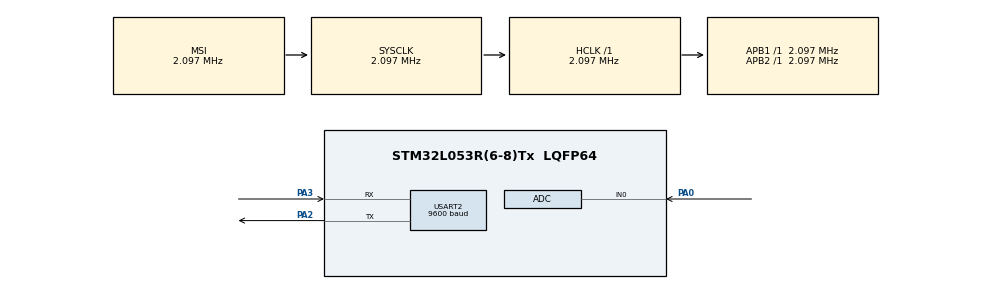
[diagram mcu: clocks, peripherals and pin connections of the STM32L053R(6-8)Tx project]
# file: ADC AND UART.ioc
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ADC.DiscontinuousConvMode=ENABLE
Mcu.Family=STM32L0
Mcu.Name=STM32L053R(6-8)Tx
Mcu.Package=LQFP64
NVIC.RCC_CRS_IRQn=true\:0\:0\:false\:false\:true\:true\:false\:true
PA0.Mode=IN0
PA0.Signal=ADC_IN0
PA2.Mode=Multiprocessor_communication
PA2.Signal=USART2_TX
PA3.Mode=Multiprocessor_communication
PA3.Signal=USART2_RX
PH0-OSC_IN.Mode=HSE-External-Oscillator
PH0-OSC_IN.Signal=RCC_OSC_IN
PH1-OSC_OUT.Mode=HSE-External-Oscillator
PH1-OSC_OUT.Signal=RCC_OSC_OUT
ProjectManager.HeapSize=0x200
ProjectManager.StackSize=0x400
ProjectManager.TargetToolchain=STM32CubeIDE
RCC.AHBFreq_Value=2097000
RCC.APB1Freq_Value=2097000
RCC.APB1TimFreq_Value=2097000
RCC.APB2Freq_Value=2097000
RCC.APB2TimFreq_Value=2097000
RCC.HSE_VALUE=8000000
RCC.HSI16_VALUE=16000000
RCC.HSI48_VALUE=48000000
RCC.HSI_VALUE=16000000
RCC.LSE_VALUE=32768
RCC.MSI_VALUE=2097000
RCC.SYSCLKFreq_VALUE=2097000
RCC.VCOOutputFreq_Value=48000000
USART2.BaudRate=9600
USART2.VirtualMode-Multiprocessor_communication=VM_ASYNC
board=custom

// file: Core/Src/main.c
/* USER CODE BEGIN Header */
/**
  ******************************************************************************
  * @file           : main.c
  * @brief          : Main program body
  ******************************************************************************
  * @attention
  *
  * Copyright (c) 2023 STMicroelectronics.
  * All rights reserved.
  *
  * This software is licensed under terms that can be found in the LICENSE file
  * in the root directory of this software component.
  * If no LICENSE file comes with this software, it is provided AS-IS.
  *
  ******************************************************************************
  */
/* USER CODE END Header */
#include "main.h"

ADC_HandleTypeDef hadc;

UART_HandleTypeDef huart2;

/* USER CODE BEGIN PV */
int value;
char rxdata[2];
int a = 0;

/* USER CODE END PV */

void SystemClock_Config(void);
static void MX_GPIO_Init(void);
static void MX_USART2_UART_Init(void);
static void MX_ADC_Init(void);

/* USER CODE BEGIN PFP */

#ifdef __GNUC__

  #define PUTCHAR_PROTOTYPE int __io_putchar(int ch)
#else
  #define PUTCHAR_PROTOTYPE int fputc(int  ch, FILE *f)

#endif /*__GNUC__*/

/* USER CODE END PFP */

/* USER CODE BEGIN 0 */

PUTCHAR_PROTOTYPE
{
  HAL_UART_Transmit(&huart2, (uint8_t *)&ch, 1, 0xFFFF);

  return ch;
}
/* USER CODE END 0 */

int main(void)
{

  /* MCU Configuration--------------------------------------------------------*/

  /* Reset of all peripherals, Initializes the Flash interface and the Systick. */  HAL_Init();

  /* Configure the system clock */
  SystemClock_Config();

  /* Initialize all configured peripherals */
  MX_GPIO_Init();
  MX_USART2_UART_Init();
  MX_ADC_Init();
  /* USER CODE BEGIN 2 */
  //HAL_UART_Receive(&huart2, rxdata, 8, 1000);
  /* USER CODE END 2 */

  /* Infinite loop */
  while (1)
  {

    /* USER CODE BEGIN 3 */

	  HAL_UART_Receive(&huart2, rxdata, 8, 1000);

	  HAL_ADC_Start(&hadc);
	  HAL_ADC_PollForConversion(&hadc, 100);
	  value = (int) HAL_ADC_GetValue(&hadc);
	  HAL_Delay(150);
	  HAL_ADC_Stop(&hadc);

	 if (rxdata[0] == 's'){
         a = a+1;
		 if ( value <=9){
		     printf("000%d\n\r", value);
		   }

		 if (value >=10 && value <=99){
		    printf("00%d\n\r", value);
		   }

		 if (value >=100 && value <=999){
		    printf("0%d\n\r", value);
		   }

		 if(value >=1000){
		    printf("%d\n\r", value);
		   }

	 }

  }
  /* USER CODE END 3 */
}

void SystemClock_Config(void)
{
  RCC_OscInitTypeDef RCC_OscInitStruct = {0};
  RCC_ClkInitTypeDef RCC_ClkInitStruct = {0};
  RCC_PeriphCLKInitTypeDef PeriphClkInit = {0};

  /** Configure the main internal regulator output voltage
  */
  __HAL_PWR_VOLTAGESCALING_CONFIG(PWR_REGULATOR_VOLTAGE_SCALE1);

  /** Initializes the RCC Oscillators according to the specified parameters
  * in the RCC_OscInitTypeDef structure.
  */
  RCC_OscInitStruct.OscillatorType = RCC_OSCILLATORTYPE_MSI;
  RCC_OscInitStruct.MSIState = RCC_MSI_ON;
  RCC_OscInitStruct.MSICalibrationValue = 0;
  RCC_OscInitStruct.MSIClockRange = RCC_MSIRANGE_5;
  RCC_OscInitStruct.PLL.PLLState = RCC_PLL_NONE;
  if (HAL_RCC_OscConfig(&RCC_OscInitStruct) != HAL_OK)
  {
    Error_Handler();
  }

  /** Initializes the CPU, AHB and APB buses clocks
  */
  RCC_ClkInitStruct.ClockType = RCC_CLOCKTYPE_HCLK|RCC_CLOCKTYPE_SYSCLK
                              |RCC_CLOCKTYPE_PCLK1|RCC_CLOCKTYPE_PCLK2;
  RCC_ClkInitStruct.SYSCLKSource = RCC_SYSCLKSOURCE_MSI;
  RCC_ClkInitStruct.AHBCLKDivider = RCC_SYSCLK_DIV1;
  RCC_ClkInitStruct.APB1CLKDivider = RCC_HCLK_DIV1;
  RCC_ClkInitStruct.APB2CLKDivider = RCC_HCLK_DIV1;

  if (HAL_RCC_ClockConfig(&RCC_ClkInitStruct, FLASH_LATENCY_0) != HAL_OK)
  {
    Error_Handler();
  }
  PeriphClkInit.PeriphClockSelection = RCC_PERIPHCLK_USART2;
  PeriphClkInit.Usart2ClockSelection = RCC_USART2CLKSOURCE_PCLK1;
  if (HAL_RCCEx_PeriphCLKConfig(&PeriphClkInit) != HAL_OK)
  {
    Error_Handler();
  }
}

static void MX_ADC_Init(void)
{

  ADC_ChannelConfTypeDef sConfig = {0};

  /** Configure the global features of the ADC (Clock, Resolution, Data Alignment and number of conversion)
  */
  hadc.Instance = ADC1;
  hadc.Init.OversamplingMode = DISABLE;
  hadc.Init.ClockPrescaler = ADC_CLOCK_SYNC_PCLK_DIV1;
  hadc.Init.Resolution = ADC_RESOLUTION_12B;
  hadc.Init.SamplingTime = ADC_SAMPLETIME_1CYCLE_5;
  hadc.Init.ScanConvMode = ADC_SCAN_DIRECTION_FORWARD;
  hadc.Init.DataAlign = ADC_DATAALIGN_RIGHT;
  hadc.Init.ContinuousConvMode = DISABLE;
  hadc.Init.DiscontinuousConvMode = ENABLE;
  hadc.Init.ExternalTrigConvEdge = ADC_EXTERNALTRIGCONVEDGE_NONE;
  hadc.Init.ExternalTrigConv = ADC_SOFTWARE_START;
  hadc.Init.DMAContinuousRequests = DISABLE;
  hadc.Init.EOCSelection = ADC_EOC_SINGLE_CONV;
  hadc.Init.Overrun = ADC_OVR_DATA_PRESERVED;
  hadc.Init.LowPowerAutoWait = DISABLE;
  hadc.Init.LowPowerFrequencyMode = ENABLE;
  hadc.Init.LowPowerAutoPowerOff = DISABLE;
  if (HAL_ADC_Init(&hadc) != HAL_OK)
  {
    Error_Handler();
  }

  /** Configure for the selected ADC regular channel to be converted.
  */
  sConfig.Channel = ADC_CHANNEL_0;
  sConfig.Rank = ADC_RANK_CHANNEL_NUMBER;
  if (HAL_ADC_ConfigChannel(&hadc, &sConfig) != HAL_OK)
  {
    Error_Handler();
  }

}

static void MX_USART2_UART_Init(void)
{

  huart2.Instance = USART2;
  huart2.Init.BaudRate = 9600;
  huart2.Init.WordLength = UART_WORDLENGTH_8B;
  huart2.Init.StopBits = UART_STOPBITS_1;
  huart2.Init.Parity = UART_PARITY_NONE;
  huart2.Init.Mode = UART_MODE_TX_RX;
  huart2.Init.HwFlowCtl = UART_HWCONTROL_NONE;
  huart2.Init.OverSampling = UART_OVERSAMPLING_16;
  huart2.Init.OneBitSampling = UART_ONE_BIT_SAMPLE_DISABLE;
  huart2.AdvancedInit.AdvFeatureInit = UART_ADVFEATURE_NO_INIT;
  if (HAL_MultiProcessor_Init(&huart2, 0, UART_WAKEUPMETHOD_IDLELINE) != HAL_OK)
  {
    Error_Handler();
  }

}

static void MX_GPIO_Init(void)
{

  /* GPIO Ports Clock Enable */
  __HAL_RCC_GPIOH_CLK_ENABLE();
  __HAL_RCC_GPIOA_CLK_ENABLE();

}

/* USER CODE BEGIN 4 */
void HAL_UART_RxCpltCallback(UART_HandleTypeDef *huart)
{
  /* Prevent unused argument(s) compilation warning */
  UNUSED(huart);

  /* NOTE : This function should not be modified, when the callback is needed,
            the HAL_UART_RxCpltCallback can be implemented in the user file.
   */
}
/* USER CODE END 4 */

void Error_Handler(void)
{
  __disable_irq();
  while (1)
  {
  }
}
